AUTOSAR XML (schema 4-1-3)
standard types defined: uint8
package /UAES/ASW/DataConstrs
  range DC_uint8: raw 0..255
package /UAES/ASW/DataTypeMappingSets
  data type mapping set DTMS_ElecDoorHndl_ComCnvTx
package /UAES/ASW/PortInterfaces
  8 x sender receiver interface:
    ComTx_u8LCK_RearLeftDoorHandleAction: invalidation-policy{data-element=ComTx_u8LCK_RearLeftDoorHandleAction/Val, handle-invalid=DONT-INVALIDATE}
      data Val: sw-calibration-access=READ-ONLY, type=uint8
    ComTx_u8LCK_RearLeftDoorHandlePosition: invalidation-policy{data-element=ComTx_u8LCK_RearLeftDoorHandlePosition/Val, handle-invalid=DONT-INVALIDATE}
      data Val: sw-calibration-access=READ-ONLY, type=uint8
    ComTx_u8LCK_RearRightDoorHandleAction: invalidation-policy{data-element=ComTx_u8LCK_RearRightDoorHandleAction/Val, handle-invalid=DONT-INVALIDATE}
      data Val: sw-calibration-access=READ-ONLY, type=uint8
    ComTx_u8LCK_RearRightDoorHandlePosition: invalidation-policy{data-element=ComTx_u8LCK_RearRightDoorHandlePosition/Val, handle-invalid=DONT-INVALIDATE}
      data Val: sw-calibration-access=READ-ONLY, type=uint8
    gEDH_u8LCK_RearLeftDoorHandleAction: invalidation-policy{data-element=gEDH_u8LCK_RearLeftDoorHandleAction/Val, handle-invalid=DONT-INVALIDATE}
      data Val: sw-calibration-access=READ-ONLY, type=uint8
    gEDH_u8LCK_RearLeftDoorHandlePosition: invalidation-policy{data-element=gEDH_u8LCK_RearLeftDoorHandlePosition/Val, handle-invalid=DONT-INVALIDATE}
      data Val: sw-calibration-access=READ-ONLY, type=uint8
    gEDH_u8LCK_RearRightDoorHandleAction: invalidation-policy{data-element=gEDH_u8LCK_RearRightDoorHandleAction/Val, handle-invalid=DONT-INVALIDATE}
      data Val: sw-calibration-access=READ-ONLY, type=uint8
    gEDH_u8LCK_RearRightDoorHandlePosition: invalidation-policy{data-element=gEDH_u8LCK_RearRightDoorHandlePosition/Val, handle-invalid=DONT-INVALIDATE}
      data Val: sw-calibration-access=READ-ONLY, type=uint8
package /UAES/ASW/SwComponentTypes
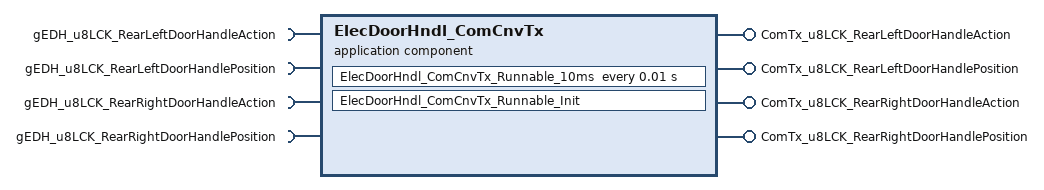
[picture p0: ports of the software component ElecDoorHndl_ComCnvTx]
  application sw component type ElecDoorHndl_ComCnvTx
    4 x provide port:
      ComTx_u8LCK_RearLeftDoorHandleAction: nonqueued-sender-com-spec{data-element=ComTx_u8LCK_RearLeftDoorHandleAction/Val, init-value=0}, provided-interface=ComTx_u8LCK_RearLeftDoorHandleAction
      ComTx_u8LCK_RearLeftDoorHandlePosition: nonqueued-sender-com-spec{data-element=ComTx_u8LCK_RearLeftDoorHandlePosition/Val, init-value=0}, provided-interface=ComTx_u8LCK_RearLeftDoorHandlePosition
      ComTx_u8LCK_RearRightDoorHandleAction: nonqueued-sender-com-spec{data-element=ComTx_u8LCK_RearRightDoorHandleAction/Val, init-value=0}, provided-interface=ComTx_u8LCK_RearRightDoorHandleAction
      ComTx_u8LCK_RearRightDoorHandlePosition: nonqueued-sender-com-spec{data-element=ComTx_u8LCK_RearRightDoorHandlePosition/Val, init-value=0}, provided-interface=ComTx_u8LCK_RearRightDoorHandlePosition
    4 x require port:
      gEDH_u8LCK_RearLeftDoorHandleAction: nonqueued-receiver-com-spec{data-element=gEDH_u8LCK_RearLeftDoorHandleAction/Val, filter=data-filter-type=ALWAYS, init-value=0}, required-interface=gEDH_u8LCK_RearLeftDoorHandleAction
      gEDH_u8LCK_RearLeftDoorHandlePosition: nonqueued-receiver-com-spec{data-element=gEDH_u8LCK_RearLeftDoorHandlePosition/Val, filter=data-filter-type=ALWAYS, init-value=0}, required-interface=gEDH_u8LCK_RearLeftDoorHandlePosition
      gEDH_u8LCK_RearRightDoorHandleAction: nonqueued-receiver-com-spec{data-element=gEDH_u8LCK_RearRightDoorHandleAction/Val, filter=data-filter-type=ALWAYS, init-value=0}, required-interface=gEDH_u8LCK_RearRightDoorHandleAction
      gEDH_u8LCK_RearRightDoorHandlePosition: nonqueued-receiver-com-spec{data-element=gEDH_u8LCK_RearRightDoorHandlePosition/Val, filter=data-filter-type=ALWAYS, init-value=0}, required-interface=gEDH_u8LCK_RearRightDoorHandlePosition
    behavior ElecDoorHndl_ComCnvTx_InternalBehavior: data-type-mapping=DTMS_ElecDoorHndl_ComCnvTx
      timing event TMT_ElecDoorHndl_ComCnvTx_Runnable_10ms: start-on-event=ElecDoorHndl_ComCnvTx_Runnable_10ms, period=0.01
      init event ElecDoorHndl_ComCnvTx_InitEvent: start-on-event=ElecDoorHndl_ComCnvTx_Runnable_Init
      runnable ElecDoorHndl_ComCnvTx_Runnable_10ms
        data-receive-point-by-arguments:
          4 x access:
            REC_gEDH_u8LCK_RearLeftDoorHandleAction_Val: accessed-variable=gEDH_u8LCK_RearLeftDoorHandleAction.Val
            REC_gEDH_u8LCK_RearLeftDoorHandlePosition_Val: accessed-variable=gEDH_u8LCK_RearLeftDoorHandlePosition.Val
            REC_gEDH_u8LCK_RearRightDoorHandleAction_Val: accessed-variable=gEDH_u8LCK_RearRightDoorHandleAction.Val
            REC_gEDH_u8LCK_RearRightDoorHandlePosition_Val: accessed-variable=gEDH_u8LCK_RearRightDoorHandlePosition.Val
        data-send-points:
          4 x access:
            SEND_ComTx_u8LCK_RearLeftDoorHandleAction_Val: accessed-variable=ComTx_u8LCK_RearLeftDoorHandleAction.Val
            SEND_ComTx_u8LCK_RearLeftDoorHandlePosition_Val: accessed-variable=ComTx_u8LCK_RearLeftDoorHandlePosition.Val
            SEND_ComTx_u8LCK_RearRightDoorHandleAction_Val: accessed-variable=ComTx_u8LCK_RearRightDoorHandleAction.Val
            SEND_ComTx_u8LCK_RearRightDoorHandlePosition_Val: accessed-variable=ComTx_u8LCK_RearRightDoorHandlePosition.Val
      runnable ElecDoorHndl_ComCnvTx_Runnable_Init
  swc implementation ElecDoorHndl_ComCnvTx_Implementation: behavior=ElecDoorHndl_ComCnvTx_InternalBehavior
    code-descriptors:
      code Default: artifact-descriptors=autosar-engineering-object={short-label=Default, category=SWSRC}
